# STM32U5F9 register map
File version: 1.1
CPU: CM33 r0p1, little endian, MPU, FPU, 4 interrupt priority bits
Registers are 32-bit, read-write, reset 0x0 unless marked. A register's access mark holds for its fields unless they carry their own. Offsets are from the block's base; [hi:lo] are bit positions; {n}, {i} and the like mark numbered series; 'fields as' and 'values as' point back to an identical list.

## SPI1 — Serial peripheral interface
Base 0x40013000
Same registers: SPI2 0x40003800, SPI3 0x46002000, SEC_SPI2 0x50003800, SEC_SPI1 0x50013000, SEC_SPI3 0x56002000
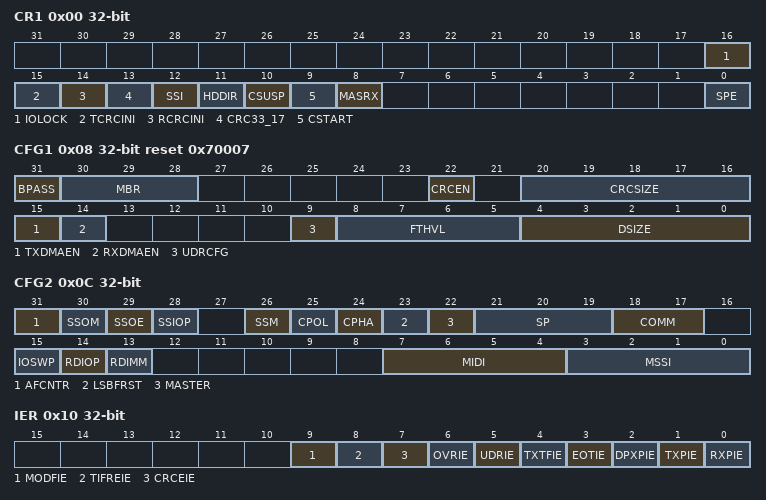
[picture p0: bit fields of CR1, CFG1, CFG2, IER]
0x00 CR1 access per field — control register 1
  [16] IOLOCK rw, [15] TCRCINI rw, [14] RCRCINI rw, [13] CRC33_17 rw, [12] SSI rw, [11] HDDIR rw, [10] CSUSP wo, [9] CSTART rw, [8] MASRX rw, [0] SPE rw
0x04 CR2 — control register 2
  [10:0] TSIZE
0x08 CFG1 reset 0x70007 — configuration register 1
  [31] BPASS
  [30:28] MBR — Master baud rate
  [22] CRCEN — Hardware CRC computation
  [20:16] CRCSIZE — Length of CRC frame to be transacted and
  [15] TXDMAEN — Tx DMA stream enable
  [14] RXDMAEN — Rx DMA stream enable
  [9] UDRCFG — Behavior of slave transmitter at
  [8:5] FTHVL — threshold level
  [4:0] DSIZE — Number of bits in at single SPI data
0x0C CFG2 — configuration register 2
  [31] AFCNTR — Alternate function GPIOs
  [30] SSOM — SS output management in master
  [29] SSOE — SS output enable
  [28] SSIOP — SS input/output polarity
  [26] SSM — Software management of SS signal
  [25] CPOL — Clock polarity
  [24] CPHA — Clock phase
  [23] LSBFRST — Data frame format
  [22] MASTER — SPI Master
  [21:19] SP — Serial Protocol
  [18:17] COMM — SPI Communication Mode
  [15] IOSWP — Swap functionality of MISO and MOSI
  [14] RDIOP
  [13] RDIMM
  [7:4] MIDI — Master Inter-Data Idleness
  [3:0] MSSI — Master SS Idleness
0x10 IER — Interrupt Enable Register
  [9] MODFIE — Mode Fault interrupt
  [8] TIFREIE — TIFRE interrupt enable
  [7] CRCEIE — CRC Interrupt enable
  [6] OVRIE — OVR interrupt enable
  [5] UDRIE — UDR interrupt enable
  [4] TXTFIE — TXTFIE interrupt enable
  [3] EOTIE — EOT, SUSP and TXC interrupt
  [2] DPXPIE — DXP interrupt enabled
  [1] TXPIE — TXP interrupt enable
  [0] RXPIE — RXP Interrupt Enable
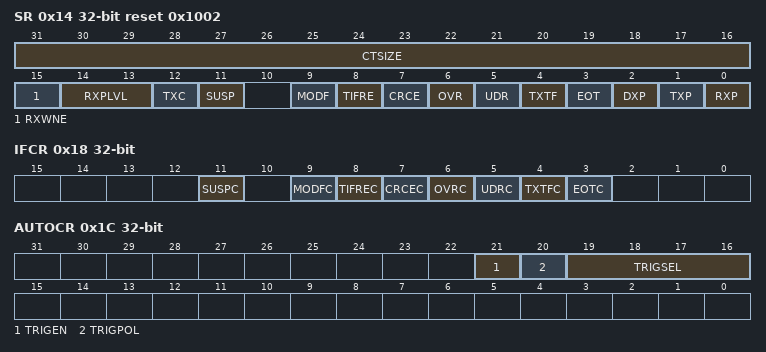
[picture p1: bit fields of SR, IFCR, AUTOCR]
0x14 SR ro reset 0x1002 — Status Register
  [31:16] CTSIZE — Number of data frames remaining in
  [15] RXWNE — RxFIFO Word Not Empty
  [14:13] RXPLVL — RxFIFO Packing LeVeL
  [12] TXC — TxFIFO transmission
  [11] SUSP — SUSPend
  [9] MODF — Mode Fault
  [8] TIFRE — TI frame format error
  [7] CRCE — CRC Error
  [6] OVR — Overrun
  [5] UDR — Underrun at slave transmission
  [4] TXTF — Transmission Transfer
  [3] EOT — End Of Transfer
  [2] DXP — Duplex Packet
  [1] TXP — Tx-Packet space available
  [0] RXP — Rx-Packet available
0x18 IFCR wo — Interrupt/Status Flags Clear
  [11] SUSPC — SUSPend flag clear
  [9] MODFC — Mode Fault flag clear
  [8] TIFREC — TI frame format error flag
  [7] CRCEC — CRC Error flag clear
  [6] OVRC — Overrun flag clear
  [5] UDRC — Underrun flag clear
  [4] TXTFC — Transmission Transfer Filled flag
  [3] EOTC — End Of Transfer flag clear
0x1C AUTOCR — SPI autonomous mode control register
  [21] TRIGEN, [20] TRIGPOL, [19:16] TRIGSEL
0x20 TXDR wo — Transmit Data Register
  [31:0] TXDR — Transmit data register
0x30 RXDR ro — Receive Data Register
  [31:0] RXDR — Receive data register
0x40 CRCPOLY reset 0x107 — Polynomial Register
  [31:0] CRCPOLY — CRC polynomial register
0x44 TXCRC ro — Transmitter CRC Register
  [31:0] TXCRC — CRC register for
0x48 RXCRC ro — Receiver CRC Register
  [31:0] RXCRC — CRC register for receiver
0x4C UDRDR — Underrun Data Register
  [31:0] UDRDR — Data at slave underrun

## TAMP — Tamper and backup registers
Base 0x46007C00
Same registers: SEC_TAMP 0x56007C00
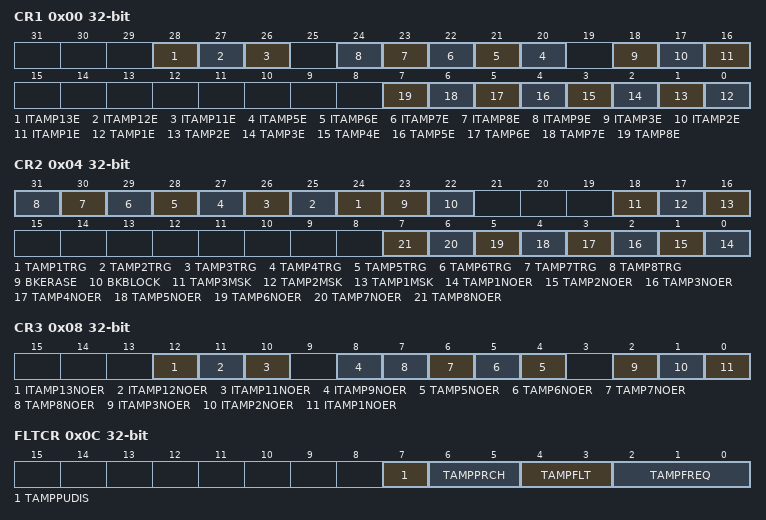
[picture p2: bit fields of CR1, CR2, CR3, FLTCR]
0x00 CR1 — control register 1
  [28] ITAMP13E
  [27] ITAMP12E
  [26] ITAMP11E — TAMP1E
  [n+15] ITAMP{n}E (n=5..9)
  [18] ITAMP3E
  [17] ITAMP2E
  [16] ITAMP1E
  [n-1] TAMP{n}E (n=1..8)
0x04 CR2 — control register 2
  [n+23] TAMP{n}TRG (n=1..8), [23] BKERASE, [22] BKBLOCK, [18] TAMP3MSK, [17] TAMP2MSK, [16] TAMP1MSK, [n-1] TAMP{n}NOER (n=1..8)
0x08 CR3 — control register 3
  [12] ITAMP13NOER, [11] ITAMP12NOER, [10] ITAMP11NOER, [8] ITAMP9NOER, [n-1] TAMP{n}NOER (n=5..8), [2] ITAMP3NOER, [1] ITAMP2NOER, [0] ITAMP1NOER
0x0C FLTCR — TAMP filter control register
  [7] TAMPPUDIS, [6:5] TAMPPRCH, [4:3] TAMPFLT, [2:0] TAMPFREQ
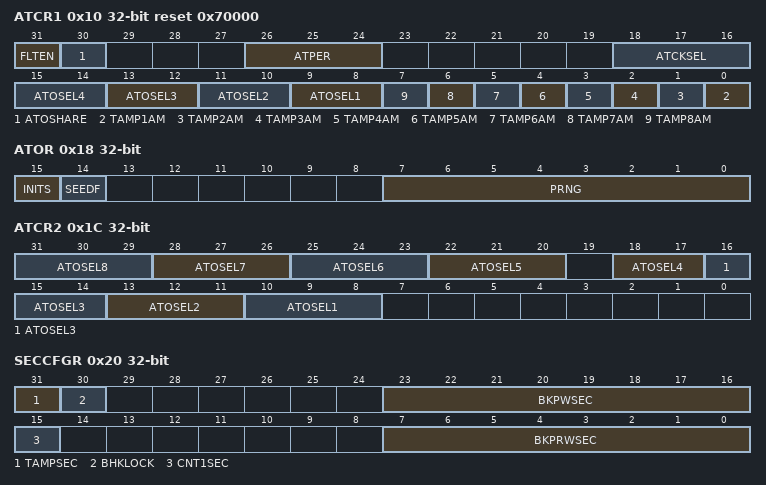
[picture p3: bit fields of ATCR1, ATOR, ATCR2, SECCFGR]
0x10 ATCR1 reset 0x70000 — TAMP active tamper control register
  [31] FLTEN — ATOSHARE
  [30] ATOSHARE
  [26:24] ATPER
  [18:16] ATCKSEL
  [2n+7:2n+6] ATOSEL{n} (n=1..4)
  [n-1] TAMP{n}AM (n=1..8)
0x14 ATSEEDR — TAMP active tamper seed register
  [31:0] SEED
0x18 ATOR ro — TAMP active tamper output register
  [15] INITS, [14] SEEDF, [7:0] PRNG
0x1C ATCR2 — TAMP active tamper control register 2
  [3n+7:3n+5] ATOSEL{n} (n=5..8), [18:17] ATOSEL4, [16:14] ATOSEL3, [13:11] ATOSEL2, [10:8] ATOSEL1
0x20 SECCFGR — TAMP secure mode register
  [31] TAMPSEC, [30] BHKLOCK, [23:16] BKPWSEC, [15] CNT1SEC, [7:0] BKPRWSEC
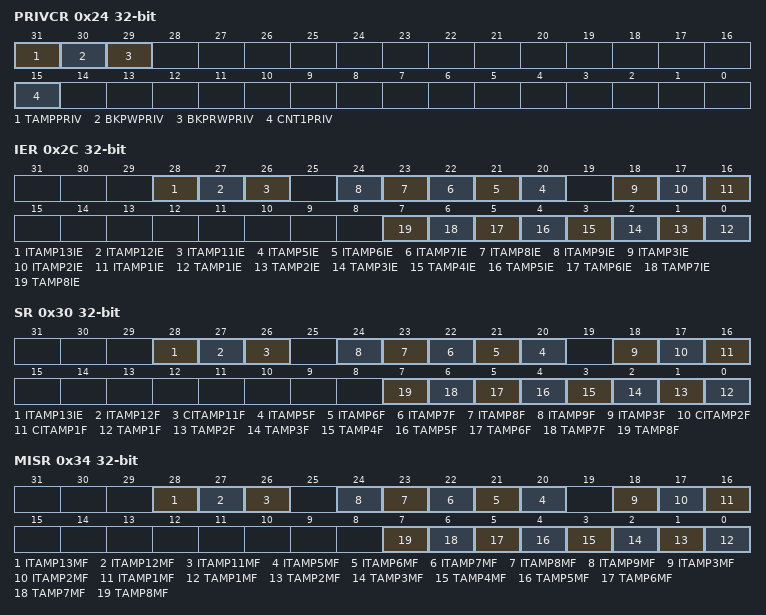
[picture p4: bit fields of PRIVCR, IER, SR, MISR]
0x24 PRIVCR — TAMP privilege mode control register
  [31] TAMPPRIV, [30] BKPWPRIV, [29] BKPRWPRIV, [15] CNT1PRIV
0x2C IER — TAMP interrupt enable register
  [28] ITAMP13IE, [27] ITAMP12IE, [26] ITAMP11IE, [n+15] ITAMP{n}IE (n=5..9), [18] ITAMP3IE, [17] ITAMP2IE, [16] ITAMP1IE, [n-1] TAMP{n}IE (n=1..8)
0x30 SR ro — TAMP status register
  [28] ITAMP13IE, [27] ITAMP12F, [26] CITAMP11F, [n+15] ITAMP{n}F (n=5..9), [18] ITAMP3F, [17] CITAMP2F, [16] CITAMP1F, [n-1] TAMP{n}F (n=1..8)
0x34 MISR ro — TAMP masked interrupt status register
  [28] ITAMP13MF, [27] ITAMP12MF, [26] ITAMP11MF, [n+15] ITAMP{n}MF (n=5..9), [18] ITAMP3MF, [17] ITAMP2MF, [16] ITAMP1MF, [n-1] TAMP{n}MF (n=1..8)
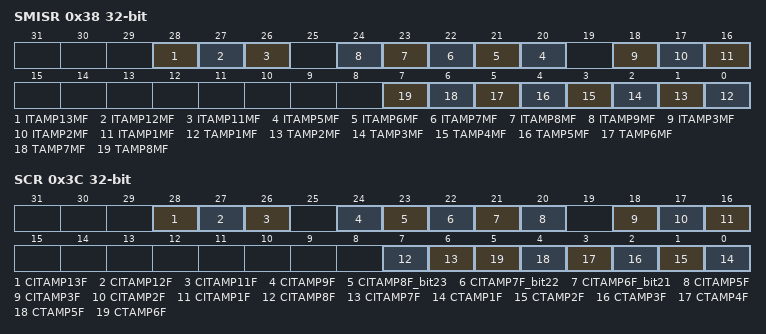
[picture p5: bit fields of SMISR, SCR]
0x38 SMISR ro — TAMP secure masked interrupt status register
  fields as MISR
0x3C SCR — TAMP status clear register
  [28] CITAMP13F
  [27] CITAMP12F
  [26] CITAMP11F
  [24] CITAMP9F
  [23] CITAMP8F_bit23
  [22] CITAMP7F_bit22
  [21] CITAMP6F_bit21
  [20] CITAMP5F
  [18] CITAMP3F
  [17] CITAMP2F
  [16] CITAMP1F
  [7] CITAMP8F — CITAMP3F
  [6] CITAMP7F — CITAMP3F
  [n-1] CTAMP{n}F (n=1..6)
0x40 COUNT1R ro — TAMP monotonic counter 1register
  [31:0] COUNT
0x54 ERCFGR — TAMP erase configuration register
  [0] ERCFG0
{0x100+4i} BKP{i}R (i=0..31) — TAMP backup register
  [31:0] BKP
